# STM32H7RSxx register map
File version: 0.1
CPU: CM7 r0p1, little endian, MPU, FPU, 4 interrupt priority bits
Registers are 32-bit, read-write, reset 0x0 unless marked. A register's access mark holds for its fields unless they carry their own. Offsets are from the block's base; lines under a group give offsets from that group; [hi:lo] are bit positions; {n}, {i} and the like mark numbered series; 'fields as' and 'values as' point back to an identical list; <NAME> marks a mode.

## Memory map
0x40002C00 WWDG size 0x400
0x40003800 SPI2 size 0x400
0x40003C00 SPI3 size 0x400
0x40004400 USART2 size 0x400
0x40004800 USART3 size 0x400
0x40004C00 UART4 size 0x400
0x40005000 UART5 size 0x400
0x40005400 I2C1 size 0x400 — Inter-integrated circuit
0x40005400 I3C1 size 0x400 — Improved inter-integrated circuit
0x40005800 I2C2 size 0x400
0x40005C00 I2C3 size 0x400
0x40006C00 HDMI_CEC size 0x400
0x40007800 UART7 size 0x400
0x40007C00 UART8 size 0x400
0x4000A000 FDCAN1 size 0x400
0x4000A400 FDCAN2 size 0x400
0x4000EC00 UCPD1 size 0x400 — USB Power Delivery interface
0x40022000 ADC1 size 0x400 — Analog to digital converter
0x40022100 ADC2 size 0x400
0x42001000 USART1 size 0x400 — Universal synchronous asynchronous receiver transmitter
0x42003000 SPI1 size 0x400 — Serial peripheral interface
0x42003400 SPI4 size 0x400
0x42005000 SPI5 size 0x400
0x48020000 RNG size 0x400 — True random number generator
0x48022000 PKA size 0x4000 — Public key accelerator
0x52002000 FLASH size 0x1000 — Embedded Flash memory
0x58000000 EXTI size 0x400 — External interrupt/event controller
0x58000C00 LPUART1 size 0x400 — Universal synchronous asynchronous receiver transmitter
0x58001400 SPI6 size 0x400
0x58004000 RTC size 0x400 — Real-time clock
0x58004400 TAMP size 0x400 — Tamper and backup registers
0x58020000 GPIOA size 0x400 — General-purpose I/Os
0x58020400 GPIOB size 0x400 — General-purpose I/Os
0x58020800 GPIOC size 0x400 — General-purpose I/Os
0x58020C00 GPIOD size 0x400 — General-purpose I/Os
0x58021000 GPIOE size 0x400 — General-purpose I/Os
0x58021400 GPIOF size 0x400 — General-purpose I/Os
0x58021800 GPIOG size 0x400 — General-purpose I/Os
0x58021C00 GPIOH size 0x400 — General-purpose I/Os
0x58023000 GPIOM size 0x400 — General-purpose I/Os
0x58023400 GPION size 0x400 — General-purpose I/Os
0x58023800 GPIOO size 0x400 — General-purpose I/Os
0x58023C00 GPIOP size 0x400 — General-purpose I/Os
0x58024400 RCC size 0x400
0x58024800 PWR size 0x400 — Power control

## Interrupts
1 PDV_PVD_AVD (EXTI) — PVD and AVD signals are OR-ed together on the same EXTI event input
4 TAMP — Tamper global interrupts
4 WWDG — Window Watchdog interrupt
5 RCC — RCC interrupt
8 FLASH — Flash memory
{n+11} EXTI{n} (EXTI) (n=0..15) — EXTI line{n} interrupt
35 PKA — PKA global interrupt
37 ADC1 — ADC1 global interrupt
37 RNG — RNG global interrupt
51 I2C1_EV (I2C1) — I2C1 event interrupt
52 I2C1_ER (I2C1) — I2C1 error interrupt
53 I2C2_EV (I2C2) — I2C2 event interrupt
53 I2C3_EV (I2C3) — I2C3 event interrupt
54 I2C2_ER (I2C2) — I2C2 error interrupt
54 I2C3_ER (I2C3) — I2C3 error interrupt
58 SPI1 — SPI1 global interrupt
59 SPI2 — SPI2 global interrupt
60 SPI3 — SPI3 global interrupt
61 SPI4 — SPI4 global interrupt
62 SPI5 — SPI5 global interrupt
63 SPI6 — SPI6 global interrupt
82 USART1 — USART1 global interrupt
90 USART2 — USART2 global interrupt
91 USART3 — USART3 global interrupt
92 UART4 — UART4 global interrupt
93 UART5 — UART5 global interrupt
94 UART7 — UART7 global interrupt
95 UART8 — UART8 global interrupt
123 I3C1_EV (I3C1) — I3C1 event interrupt
124 I3C1_ER (I3C1) — I3C1 error interrupt
128 UCPD1 — UCPD1 global interrupt
129 CEC (HDMI_CEC) — CEC global interrupt
131 LPUART1 — LPUART1 global interrupt
152 FDCAN1_IT0 (FDCAN1) — FDCAN1 Interrupt 0
153 FDCAN1_IT1 (FDCAN1) — FDCAN1 Interrupt 1
154 FDCAN2_IT0 (FDCAN2) — FDCAN2 Interrupt 0
155 FDCAN2_IT1 (FDCAN2) — FDCAN2 Interrupt 1

## EXTI — External interrupt/event controller
Base 0x58000000
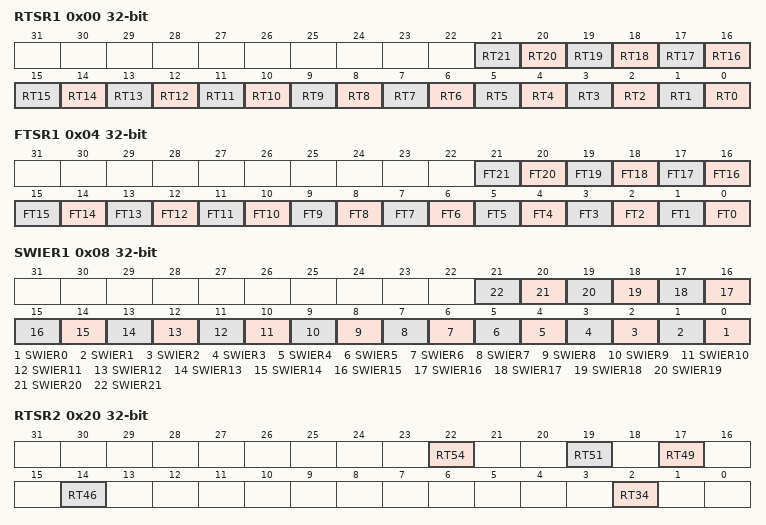
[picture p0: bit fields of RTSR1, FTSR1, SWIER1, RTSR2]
0x00 RTSR1 — EXTI rising trigger selection register
  [n] RT{n} (n=0..21) — Rising trigger event configuration bit of configurable event input x
0x04 FTSR1 — EXTI falling trigger selection register
  [n] FT{n} (n=0..21) — Falling trigger event configuration bit of configurable event input x
0x08 SWIER1 — EXTI software interrupt event register
  [n] SWIER{n} (n=0..21) — Software interrupt on event x
0x20 RTSR2 — EXTI rising trigger selection 2 register
  [22] RT54 — Rising trigger event configuration bit of configurable event input x
  [19] RT51 — Rising trigger event configuration bit of configurable event input x
  [17] RT49 — Rising trigger event configuration bit of configurable event input x
  [14] RT46 — Rising trigger event configuration bit of configurable event input x
  [2] RT34 — Rising trigger event configuration bit of configurable event input x
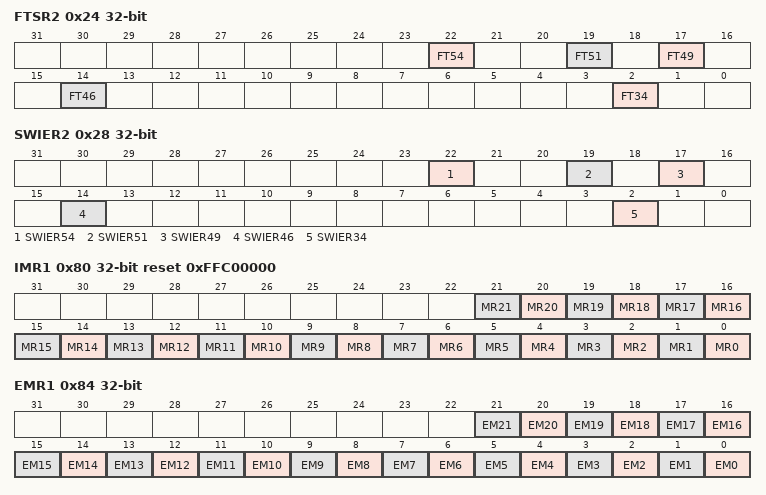
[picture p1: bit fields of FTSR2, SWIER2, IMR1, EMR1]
0x24 FTSR2 — EXTI falling trigger selection 2 register
  [22] FT54 — Falling trigger event configuration bit of configurable event input x
  [19] FT51 — Falling trigger event configuration bit of configurable event input x
  [17] FT49 — Falling trigger event configuration bit of configurable event input x
  [14] FT46 — Falling trigger event configuration bit of configurable event input x
  [2] FT34 — Falling trigger event configuration bit of configurable event input x
0x28 SWIER2 — EXTI software interrupt event 2 register
  [22] SWIER54 — Software interrupt on event x
  [19] SWIER51 — Software interrupt on event x
  [17] SWIER49 — Software interrupt on event x
  [14] SWIER46 — Software interrupt on event x
  [2] SWIER34 — Software interrupt on event x
0x80 IMR1 reset 0xFFC00000 — EXTI CPU interrupt mask on direct event input
  [n] MR{n} (n=0..21) — Interrupt request from line x is masked
0x84 EMR1 — EXTI CPU wakeup with event mask register
  [n] EM{n} (n=0..21) — CPU wakeup with event generation mask on event input
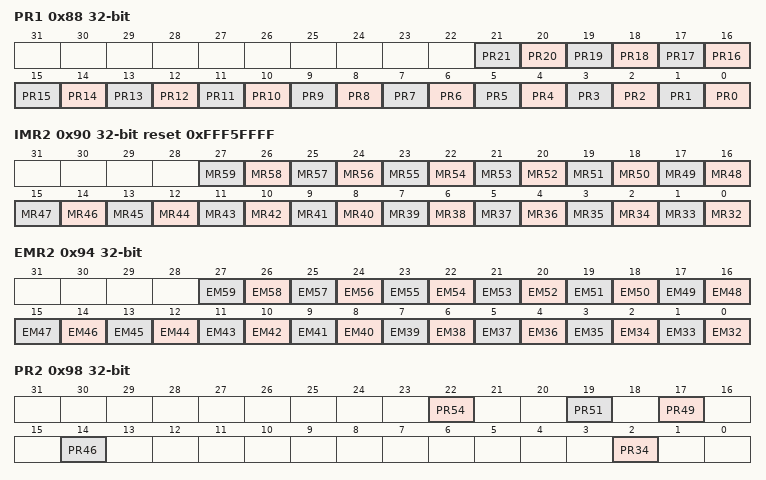
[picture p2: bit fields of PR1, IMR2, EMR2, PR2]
0x88 PR1 — EXTI pending egister
  [n] PR{n} (n=0..21) — configurable event inputs x pending bit
0x90 IMR2 reset 0xFFF5FFFF — EXTI CPU interrupt mask on direct event input
  [n-32] MR{n} (n=32..59) — Interrupt request from line x is masked
0x94 EMR2 — EXTI CPU wakeup with event mask register
  [n-32] EM{n} (n=32..59) — CPU wakeup with event generation mask on event input
0x98 PR2 — EXTI pending egister
  [22] PR54 — configurable event inputs x pending bit
  [19] PR51 — configurable event inputs x pending bit
  [17] PR49 — configurable event inputs x pending bit
  [14] PR46 — configurable event inputs x pending bit
  [2] PR34 — configurable event inputs x pending bit
0xA0 IMR3 reset 0xF8BFFFF — EXTI CPU interrupt mask on direct event input
  [13] MR77 — Interrupt request from line x is masked
0xA4 EMR3 — EXTI CPU wakeup with event mask register
  [13] EM77 — CPU wakeup with event generation mask on event input

## Notices in the file
Copyright (c) 2022 STMicroelectronics.
SPDX-License-Identifier: Apache-2.0
Licensed under the Apache License, Version 2.0 (the "License");
you may not use this file except in compliance with the License.
You may obtain a copy of the License at
http://www.apache.org/licenses/LICENSE-2.0
Unless required by applicable law or agreed to in writing, software
distributed under the License is distributed on an "AS IS" BASIS,
WITHOUT WARRANTIES OR CONDITIONS OF ANY KIND, either express or implied.
See the License for the specific language governing permissions and
limitations under the License.
